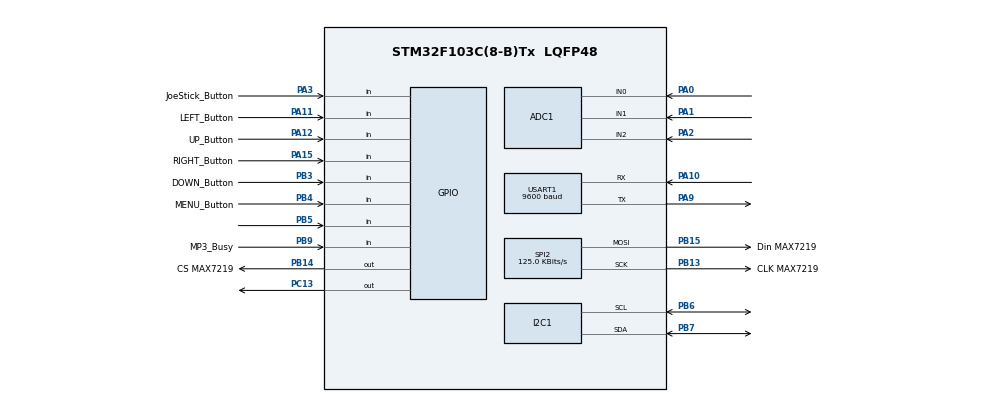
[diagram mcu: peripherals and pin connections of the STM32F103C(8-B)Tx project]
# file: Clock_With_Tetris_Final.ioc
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ADC1.Channel-0\#ChannelRegularConversion=ADC_CHANNEL_2
ADC1.ContinuousConvMode=DISABLE
ADC1.NbrOfConversion=1
ADC1.NbrOfConversionFlag=1
ADC1.Rank-0\#ChannelRegularConversion=1
ADC1.SamplingTime-0\#ChannelRegularConversion=ADC_SAMPLETIME_239CYCLES_5
ADC1.master=1
I2C1.I2C_Mode=I2C_Fast
Mcu.Family=STM32F1
Mcu.Name=STM32F103C(8-B)Tx
Mcu.Package=LQFP48
NVIC.ADC1_2_IRQn=true\:0\:0\:false\:false\:true\:true\:true\:true
NVIC.PriorityGroup=NVIC_PRIORITYGROUP_4
NVIC.SPI2_IRQn=true\:0\:0\:false\:false\:true\:true\:true\:true
NVIC.USART1_IRQn=true\:0\:0\:false\:false\:true\:true\:true\:true
PA0-WKUP.Signal=ADCx_IN0
PA1.Signal=ADCx_IN1
PA10.Mode=Asynchronous
PA10.Signal=USART1_RX
PA11.GPIO_Label=LEFT_Button
PA11.GPIO_PuPd=GPIO_PULLUP
PA11.Signal=GPIO_Input
PA12.GPIO_Label=UP_Button
PA12.GPIO_PuPd=GPIO_PULLUP
PA12.Signal=GPIO_Input
PA13.Mode=Serial_Wire
PA13.Signal=SYS_JTMS-SWDIO
PA14.Mode=Serial_Wire
PA14.Signal=SYS_JTCK-SWCLK
PA15.GPIO_Label=RIGHT_Button
PA15.GPIO_PuPd=GPIO_PULLUP
PA15.Signal=GPIO_Input
PA2.Signal=ADCx_IN2
PA3.GPIO_Label=JoeStick_Button
PA3.GPIO_PuPd=GPIO_PULLUP
PA3.Signal=GPIO_Input
PA9.Mode=Asynchronous
PA9.Signal=USART1_TX
PB13.GPIO_Label=CLK MAX7219
PB13.Mode=TX_Only_Simplex_Unidirect_Master
PB13.Signal=SPI2_SCK
PB14.GPIO_Label=CS MAX7219
PB14.GPIO_PuPd=GPIO_NOPULL
PB14.Signal=GPIO_Output
PB15.GPIO_Label=Din MAX7219
PB15.Mode=TX_Only_Simplex_Unidirect_Master
PB15.Signal=SPI2_MOSI
PB3.GPIO_Label=DOWN_Button
PB3.GPIO_PuPd=GPIO_PULLUP
PB3.Signal=GPIO_Input
PB4.GPIO_Label=MENU_Button
PB4.GPIO_PuPd=GPIO_PULLUP
PB4.Signal=GPIO_Input
PB5.GPIO_PuPd=GPIO_PULLUP
PB5.Signal=GPIO_Input
PB6.Mode=I2C
PB6.Signal=I2C1_SCL
PB7.Mode=I2C
PB7.Signal=I2C1_SDA
PB9.GPIO_Label=MP3_Busy
PB9.Signal=GPIO_Input
PC13-TAMPER-RTC.Signal=GPIO_Output
ProjectManager.HeapSize=0x200
ProjectManager.StackSize=0x400
ProjectManager.TargetToolchain=STM32CubeIDE
RCC.APB1Freq_Value=8000000
RCC.APB2Freq_Value=8000000
SH.ADCx_IN0.0=ADC1_IN0,IN0
SH.ADCx_IN1.0=ADC1_IN1,IN1
SH.ADCx_IN2.0=ADC1_IN2,IN2
SPI2.BaudRatePrescaler=SPI_BAUDRATEPRESCALER_64
SPI2.CalculateBaudRate=125.0 KBits/s
SPI2.Direction=SPI_DIRECTION_2LINES
SPI2.Mode=SPI_MODE_MASTER
SPI2.VirtualType=VM_MASTER
USART1.BaudRate=9600
USART1.VirtualMode=VM_ASYNC
board=custom

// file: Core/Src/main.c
/* USER CODE BEGIN Header */
/**
  ******************************************************************************
  * @file           : main.c
  * @brief          : Main program body
  ******************************************************************************
  * @attention
  *
  * Copyright (c) 2024 STMicroelectronics.
  * All rights reserved.
  *
  * This software is licensed under terms that can be found in the LICENSE file
  * in the root directory of this software component.
  * If no LICENSE file comes with this software, it is provided AS-IS.
  *
  ******************************************************************************
  */
/* USER CODE END Header */
#include "main.h"

/* USER CODE BEGIN Includes */
#include "../../Application/App/Application.h"
/* USER CODE END Includes */

ADC_HandleTypeDef hadc1;

I2C_HandleTypeDef hi2c1;

SPI_HandleTypeDef hspi2;

UART_HandleTypeDef huart1;

void SystemClock_Config(void);
static void MX_GPIO_Init(void);
static void MX_SPI2_Init(void);
static void MX_I2C1_Init(void);
static void MX_USART1_UART_Init(void);
static void MX_ADC1_Init(void);

int main(void)
{

  /* MCU Configuration--------------------------------------------------------*/

  /* Reset of all peripherals, Initializes the Flash interface and the Systick. */
  HAL_Init();

  /* Configure the system clock */
  SystemClock_Config();

  /* Initialize all configured peripherals */
  MX_GPIO_Init();
  MX_SPI2_Init();
  MX_I2C1_Init();
  MX_USART1_UART_Init();
  MX_ADC1_Init();

  /* Infinite loop */
  /* USER CODE BEGIN WHILE */
  while (1)
  {
	  AppInit();
    /* USER CODE END WHILE */

  }
}

void SystemClock_Config(void)
{
  RCC_OscInitTypeDef RCC_OscInitStruct = {0};
  RCC_ClkInitTypeDef RCC_ClkInitStruct = {0};
  RCC_PeriphCLKInitTypeDef PeriphClkInit = {0};

  /** Initializes the RCC Oscillators according to the specified parameters
  * in the RCC_OscInitTypeDef structure.
  */
  RCC_OscInitStruct.OscillatorType = RCC_OSCILLATORTYPE_HSI;
  RCC_OscInitStruct.HSIState = RCC_HSI_ON;
  RCC_OscInitStruct.HSICalibrationValue = RCC_HSICALIBRATION_DEFAULT;
  RCC_OscInitStruct.PLL.PLLState = RCC_PLL_NONE;
  if (HAL_RCC_OscConfig(&RCC_OscInitStruct) != HAL_OK)
  {
    Error_Handler();
  }

  /** Initializes the CPU, AHB and APB buses clocks
  */
  RCC_ClkInitStruct.ClockType = RCC_CLOCKTYPE_HCLK|RCC_CLOCKTYPE_SYSCLK
                              |RCC_CLOCKTYPE_PCLK1|RCC_CLOCKTYPE_PCLK2;
  RCC_ClkInitStruct.SYSCLKSource = RCC_SYSCLKSOURCE_HSI;
  RCC_ClkInitStruct.AHBCLKDivider = RCC_SYSCLK_DIV1;
  RCC_ClkInitStruct.APB1CLKDivider = RCC_HCLK_DIV1;
  RCC_ClkInitStruct.APB2CLKDivider = RCC_HCLK_DIV1;

  if (HAL_RCC_ClockConfig(&RCC_ClkInitStruct, FLASH_LATENCY_0) != HAL_OK)
  {
    Error_Handler();
  }
  PeriphClkInit.PeriphClockSelection = RCC_PERIPHCLK_ADC;
  PeriphClkInit.AdcClockSelection = RCC_ADCPCLK2_DIV2;
  if (HAL_RCCEx_PeriphCLKConfig(&PeriphClkInit) != HAL_OK)
  {
    Error_Handler();
  }
}

static void MX_ADC1_Init(void)
{

  ADC_ChannelConfTypeDef sConfig = {0};

  /** Common config
  */
  hadc1.Instance = ADC1;
  hadc1.Init.ScanConvMode = ADC_SCAN_DISABLE;
  hadc1.Init.ContinuousConvMode = DISABLE;
  hadc1.Init.DiscontinuousConvMode = DISABLE;
  hadc1.Init.ExternalTrigConv = ADC_SOFTWARE_START;
  hadc1.Init.DataAlign = ADC_DATAALIGN_RIGHT;
  hadc1.Init.NbrOfConversion = 1;
  if (HAL_ADC_Init(&hadc1) != HAL_OK)
  {
    Error_Handler();
  }

  /** Configure Regular Channel
  */
  sConfig.Channel = ADC_CHANNEL_2;
  sConfig.Rank = ADC_REGULAR_RANK_1;
  sConfig.SamplingTime = ADC_SAMPLETIME_239CYCLES_5;
  if (HAL_ADC_ConfigChannel(&hadc1, &sConfig) != HAL_OK)
  {
    Error_Handler();
  }

}

static void MX_I2C1_Init(void)
{

  hi2c1.Instance = I2C1;
  hi2c1.Init.ClockSpeed = 400000;
  hi2c1.Init.DutyCycle = I2C_DUTYCYCLE_2;
  hi2c1.Init.OwnAddress1 = 0;
  hi2c1.Init.AddressingMode = I2C_ADDRESSINGMODE_7BIT;
  hi2c1.Init.DualAddressMode = I2C_DUALADDRESS_DISABLE;
  hi2c1.Init.OwnAddress2 = 0;
  hi2c1.Init.GeneralCallMode = I2C_GENERALCALL_DISABLE;
  hi2c1.Init.NoStretchMode = I2C_NOSTRETCH_DISABLE;
  if (HAL_I2C_Init(&hi2c1) != HAL_OK)
  {
    Error_Handler();
  }

}

static void MX_SPI2_Init(void)
{

  /* SPI2 parameter configuration*/
  hspi2.Instance = SPI2;
  hspi2.Init.Mode = SPI_MODE_MASTER;
  hspi2.Init.Direction = SPI_DIRECTION_2LINES;
  hspi2.Init.DataSize = SPI_DATASIZE_8BIT;
  hspi2.Init.CLKPolarity = SPI_POLARITY_LOW;
  hspi2.Init.CLKPhase = SPI_PHASE_1EDGE;
  hspi2.Init.NSS = SPI_NSS_SOFT;
  hspi2.Init.BaudRatePrescaler = SPI_BAUDRATEPRESCALER_64;
  hspi2.Init.FirstBit = SPI_FIRSTBIT_MSB;
  hspi2.Init.TIMode = SPI_TIMODE_DISABLE;
  hspi2.Init.CRCCalculation = SPI_CRCCALCULATION_DISABLE;
  hspi2.Init.CRCPolynomial = 10;
  if (HAL_SPI_Init(&hspi2) != HAL_OK)
  {
    Error_Handler();
  }

}

static void MX_USART1_UART_Init(void)
{

  huart1.Instance = USART1;
  huart1.Init.BaudRate = 9600;
  huart1.Init.WordLength = UART_WORDLENGTH_8B;
  huart1.Init.StopBits = UART_STOPBITS_1;
  huart1.Init.Parity = UART_PARITY_NONE;
  huart1.Init.Mode = UART_MODE_TX_RX;
  huart1.Init.HwFlowCtl = UART_HWCONTROL_NONE;
  huart1.Init.OverSampling = UART_OVERSAMPLING_16;
  if (HAL_UART_Init(&huart1) != HAL_OK)
  {
    Error_Handler();
  }

}

static void MX_GPIO_Init(void)
{
  GPIO_InitTypeDef GPIO_InitStruct = {0};

  /* GPIO Ports Clock Enable */
  __HAL_RCC_GPIOC_CLK_ENABLE();
  __HAL_RCC_GPIOA_CLK_ENABLE();
  __HAL_RCC_GPIOB_CLK_ENABLE();

  /*Configure GPIO pin Output Level */
  HAL_GPIO_WritePin(GPIOC, GPIO_PIN_13, GPIO_PIN_RESET);

  /*Configure GPIO pin Output Level */
  HAL_GPIO_WritePin(CS_MAX7219_GPIO_Port, CS_MAX7219_Pin, GPIO_PIN_RESET);

  /*Configure GPIO pin : PC13 */
  GPIO_InitStruct.Pin = GPIO_PIN_13;
  GPIO_InitStruct.Mode = GPIO_MODE_OUTPUT_PP;
  GPIO_InitStruct.Pull = GPIO_NOPULL;
  GPIO_InitStruct.Speed = GPIO_SPEED_FREQ_LOW;
  HAL_GPIO_Init(GPIOC, &GPIO_InitStruct);

  /*Configure GPIO pins : JoeStick_Button_Pin LEFT_Button_Pin UP_Button_Pin RIGHT_Button_Pin */
  GPIO_InitStruct.Pin = JoeStick_Button_Pin|LEFT_Button_Pin|UP_Button_Pin|RIGHT_Button_Pin;
  GPIO_InitStruct.Mode = GPIO_MODE_INPUT;
  GPIO_InitStruct.Pull = GPIO_PULLUP;
  HAL_GPIO_Init(GPIOA, &GPIO_InitStruct);

  /*Configure GPIO pin : CS_MAX7219_Pin */
  GPIO_InitStruct.Pin = CS_MAX7219_Pin;
  GPIO_InitStruct.Mode = GPIO_MODE_OUTPUT_PP;
  GPIO_InitStruct.Pull = GPIO_NOPULL;
  GPIO_InitStruct.Speed = GPIO_SPEED_FREQ_LOW;
  HAL_GPIO_Init(CS_MAX7219_GPIO_Port, &GPIO_InitStruct);

  /*Configure GPIO pins : DOWN_Button_Pin MENU_Button_Pin PB5 */
  GPIO_InitStruct.Pin = DOWN_Button_Pin|MENU_Button_Pin|GPIO_PIN_5;
  GPIO_InitStruct.Mode = GPIO_MODE_INPUT;
  GPIO_InitStruct.Pull = GPIO_PULLUP;
  HAL_GPIO_Init(GPIOB, &GPIO_InitStruct);

  /*Configure GPIO pin : MP3_Busy_Pin */
  GPIO_InitStruct.Pin = MP3_Busy_Pin;
  GPIO_InitStruct.Mode = GPIO_MODE_INPUT;
  GPIO_InitStruct.Pull = GPIO_NOPULL;
  HAL_GPIO_Init(MP3_Busy_GPIO_Port, &GPIO_InitStruct);

}

void Error_Handler(void)
{
  __disable_irq();
  while (1)
  {
  }
}
